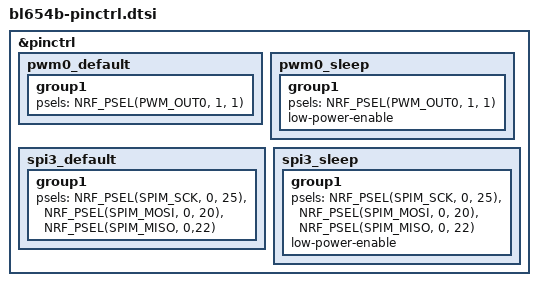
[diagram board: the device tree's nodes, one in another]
/*
 * Copyright (c) 2022 The ZMK Contributors
 * SPDX-License-Identifier: MIT
 */

&pinctrl {
    pwm0_default: pwm0_default {
        group1 {
            psels = <NRF_PSEL(PWM_OUT0, 1, 1)>;
        };
    };
    pwm0_sleep: pwm0_sleep {
        group1 {
            psels = <NRF_PSEL(PWM_OUT0, 1, 1)>;
            low-power-enable;
       };
    };


    spi3_default: spi3_default {
        group1 {
            psels = <NRF_PSEL(SPIM_SCK, 0, 25)>,
                <NRF_PSEL(SPIM_MOSI, 0, 20)>,
                <NRF_PSEL(SPIM_MISO, 0,22)>;
        };
    };
    spi3_sleep: spi3_sleep {
        group1 {
            psels = <NRF_PSEL(SPIM_SCK, 0, 25)>,
                <NRF_PSEL(SPIM_MOSI, 0, 20)>,
                <NRF_PSEL(SPIM_MISO, 0, 22)>;
            low-power-enable;
        };
    };
};



